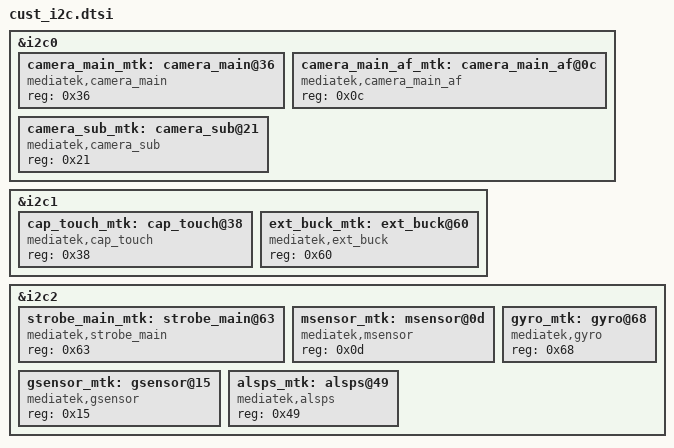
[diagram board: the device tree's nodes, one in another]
/*
 * Generated by MTK SP Drv_CodeGen Version 03.13.6	for MT6580. Copyright MediaTek Inc. (C) 2013.
 * Mon Apr  1 16:14:53 2019
 * Do Not Modify the File.
 */

/*************************
 * I2C DTSI File
*************************/

&i2c0 {
	#address-cells = <1>;
	#size-cells = <0>;
	camera_main_mtk:camera_main@36 {
		compatible = "mediatek,camera_main";
		reg = <0x36>;
		status = "okay";
	};
	camera_main_af_mtk:camera_main_af@0c {
		compatible = "mediatek,camera_main_af";
		reg = <0x0c>;
		status = "okay";
	};
	camera_sub_mtk:camera_sub@21 {
		compatible = "mediatek,camera_sub";
		reg = <0x21>;
		status = "okay";
	};
};

&i2c1 {
	#address-cells = <1>;
	#size-cells = <0>;
	cap_touch_mtk:cap_touch@38 {
		compatible = "mediatek,cap_touch";
		reg = <0x38>;
		status = "okay";
	};
	ext_buck_mtk:ext_buck@60 {
		compatible = "mediatek,ext_buck";
		reg = <0x60>;
		status = "okay";
	};
};

&i2c2 {
	#address-cells = <1>;
	#size-cells = <0>;
	strobe_main_mtk:strobe_main@63 {
		compatible = "mediatek,strobe_main";
		reg = <0x63>;
		status = "okay";
	};
	msensor_mtk:msensor@0d {
		compatible = "mediatek,msensor";
		reg = <0x0d>;
		status = "okay";
	};
	gsensor_mtk:gsensor@15 {
		compatible = "mediatek,gsensor";
		reg = <0x15>;
		status = "okay";
	};
	gyro_mtk:gyro@68 {
		compatible = "mediatek,gyro";
		reg = <0x68>;
		status = "okay";
	};
	alsps_mtk:alsps@49 {
		compatible = "mediatek,alsps";
		reg = <0x49>;
		status = "okay";
	};
};

